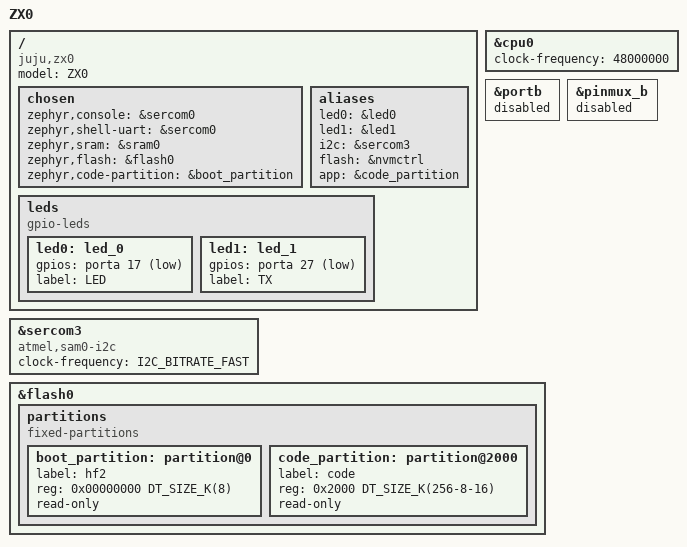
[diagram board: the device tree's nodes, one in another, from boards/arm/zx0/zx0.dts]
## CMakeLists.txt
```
# Copyright 2021 Google LLC
#
# Licensed under the Apache License, Version 2.0 (the "License");
# you may not use this file except in compliance with the License.
# You may obtain a copy of the License at
#
#      http://www.apache.org/licenses/LICENSE-2.0
#
# Unless required by applicable law or agreed to in writing, software
# distributed under the License is distributed on an "AS IS" BASIS,
# WITHOUT WARRANTIES OR CONDITIONS OF ANY KIND, either express or implied.
# See the License for the specific language governing permissions and
# limitations under the License.

cmake_minimum_required(VERSION 3.13.1)

list(APPEND BOARD_ROOT ${CMAKE_CURRENT_SOURCE_DIR})
set(BOARD zx0)

find_package(Zephyr REQUIRED HINTS $ENV{ZEPHYR_BASE})
project(zx0-bootloader)

target_sources(app PRIVATE src/main.cpp src/hf2.cpp src/i2c_sam0.cpp src/hal.cpp)
```

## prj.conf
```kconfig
#
# Copyright (c) 2021 Google LLC.
#
# SPDX-License-Identifier: Apache-2.0
#

# Disable everything to minimise the flash usage.
CONFIG_I2C=n
CONFIG_WATCHDOG=n
CONFIG_SPI=n
CONFIG_SERIAL=n
CONFIG_SAM0_EIC=n
CONFIG_MULTITHREADING=n
CONFIG_SYS_CLOCK_EXISTS=n
CONFIG_FAULT_DUMP=0
CONFIG_GEN_ISR_TABLES=n

CONFIG_BUILD_OUTPUT_HEX=y
CONFIG_SIZE_OPTIMIZATIONS=y
CONFIG_CPLUSPLUS=y
CONFIG_STD_CPP2A=y
CONFIG_IS_BOOTLOADER=y

CONFIG_FLASH=y
CONFIG_GPIO=y
CONFIG_PINMUX=y
CONFIG_SOC_FLASH_SAM0=y
```

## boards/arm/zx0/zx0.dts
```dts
/*
 * Copyright (c) 2021 Google LLC.
 *
 * SPDX-License-Identifier: Apache-2.0
 */

/dts-v1/;
#include <atmel/samd21.dtsi>

/ {
	model = "ZX0";
	compatible = "juju,zx0", "atmel,samd21e18a", "atmel,samd21";

	chosen {
		zephyr,console = &sercom0;
		zephyr,shell-uart = &sercom0;
		zephyr,sram = &sram0;
		zephyr,flash = &flash0;
		zephyr,code-partition = &boot_partition;
	};

	aliases {
		led0 = &led0;
		led1 = &led1;
		i2c = &sercom3;
		flash = &nvmctrl;
		app = &code_partition;
	};

	leds {
		compatible = "gpio-leds";
		led0: led_0 {
			gpios = <&porta 17 GPIO_ACTIVE_LOW>;
			label = "LED";
		};
		led1: led_1 {
			gpios = <&porta 27 GPIO_ACTIVE_LOW>;
			label = "TX";
		};
	};

};

&cpu0 {
	clock-frequency = <48000000>;
};

&portb {
	status = "disabled";
};

&pinmux_b {
	status = "disabled";
};

&sercom3 {
	status = "okay";
	compatible = "atmel,sam0-i2c";
	clock-frequency = <I2C_BITRATE_FAST>;
	#address-cells = <1>;
	#size-cells = <0>;
};

&flash0 {
	partitions {
		compatible = "fixed-partitions";
		#address-cells = <1>;
		#size-cells = <1>;

		boot_partition: partition@0 {
			label = "hf2";
			reg = <0x00000000 DT_SIZE_K(8)>;
			read-only;
		};

		code_partition: partition@2000 {
			label = "code";
			reg = <0x2000 DT_SIZE_K(256-8-16)>;
			read-only;
		};
	};
};
```

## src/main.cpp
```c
// Copyright 2021 Google LLC
//
// Licensed under the Apache License, Version 2.0 (the "License");
// you may not use this file except in compliance with the License.
// You may obtain a copy of the License at
//
//      http://www.apache.org/licenses/LICENSE-2.0
//
// Unless required by applicable law or agreed to in writing, software
// distributed under the License is distributed on an "AS IS" BASIS,
// WITHOUT WARRANTIES OR CONDITIONS OF ANY KIND, either express or implied.
// See the License for the specific language governing permissions and
// limitations under the License.

#include "hal.h"
#include "hf2.h"
#include "i2c_sam0.h"

static I2C i2c((SercomI2cs *)DT_REG_ADDR(DT_ALIAS(i2c)));
static HF2 hf2(HAL::flash);

void I2C::received(const uint8_t *in, uint8_t *out) { hf2.packet(in, out); }

void main(void) {
    HAL::enter_app();

    HAL::init();
    i2c.init();

    for (;;) {
        gpio_pin_toggle(HAL::led0.port, HAL::led0.pin);
        for (int spin = 0; spin < 200 * (HAL::kCyclesPerSec / 48000); spin++) {
            i2c.poll();
        }
    }
}
```

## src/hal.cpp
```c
// Copyright 2021 Google LLC
//
// Licensed under the Apache License, Version 2.0 (the "License");
// you may not use this file except in compliance with the License.
// You may obtain a copy of the License at
//
//      http://www.apache.org/licenses/LICENSE-2.0
//
// Unless required by applicable law or agreed to in writing, software
// distributed under the License is distributed on an "AS IS" BASIS,
// WITHOUT WARRANTIES OR CONDITIONS OF ANY KIND, either express or implied.
// See the License for the specific language governing permissions and
// limitations under the License.

#include "hal.h"

#include <drivers/gpio.h>

const struct gpio_dt_spec HAL::led0 = GPIO_DT_SPEC_GET_OR(DT_ALIAS(led0), gpios, {0});
const struct gpio_dt_spec HAL::led1 = GPIO_DT_SPEC_GET_OR(DT_ALIAS(led1), gpios, {0});
const device *HAL::flash = DEVICE_DT_GET(DT_ALIAS(flash));

enum class DoubleTap : uint32_t {
    None = 0,
    Magic = 0xf01669ef,
    QuickBoot = 0xf02669ef,
};

DoubleTap &double_tap = *(DoubleTap *)(HMCRAMC0_ADDR + HMCRAMC0_SIZE - 4);

void HAL::init() {
    gpio_pin_configure_dt(&led0, GPIO_OUTPUT_INACTIVE);
    gpio_pin_configure_dt(&led1, GPIO_OUTPUT_INACTIVE);
}

static void wait(uint32_t millis) {
    millis *= HAL::kCyclesPerSec / 10000;

    while (millis--) {
        asm("nop; nop; nop; nop; nop");
    }
}

int HAL::enter_app() {
    uint32_t start = *(uint32_t *)(kAppStart + 4);

    if (start <= kAppStart || start >= FLASH_SIZE) {
        /* Stay in bootloader */
        return -ENOENT;
    }

    auto state = double_tap;
    double_tap = DoubleTap::None;

    if (PM->RCAUSE.bit.POR) {
        // Just turned on, continue straight into the app.
    } else {
        switch (state) {
            case DoubleTap::Magic:
                return 0;
            case DoubleTap::QuickBoot:
                break;
            default:
                double_tap = DoubleTap::Magic;
                // Spin to give the user time to press reset again.
                wait(500);
                double_tap = DoubleTap::None;
                break;
        }
    }

    // Enter the app.
    __set_MSP(*(uint32_t *)kAppStart);
    SCB->VTOR = (kAppStart & SCB_VTOR_TBLOFF_Msk);
    asm("bx %0" ::"r"(start));

    return 0;
}
```

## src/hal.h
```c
// Copyright 2021 Google LLC
//
// Licensed under the Apache License, Version 2.0 (the "License");
// you may not use this file except in compliance with the License.
// You may obtain a copy of the License at
//
//      http://www.apache.org/licenses/LICENSE-2.0
//
// Unless required by applicable law or agreed to in writing, software
// distributed under the License is distributed on an "AS IS" BASIS,
// WITHOUT WARRANTIES OR CONDITIONS OF ANY KIND, either express or implied.
// See the License for the specific language governing permissions and
// limitations under the License.

#pragma once

#include <device.h>
#include <drivers/gpio.h>
#include <soc.h>

// Hardware abstraction. Contains the flash details, LEDs, and other devices.
class HAL {
   public:
    // Initialise the common devices.
    static void init();
    // Try to enter the application. Returns if the application is invalid.
    static int enter_app();

    static constexpr size_t kFlashSize = FLASH_SIZE;
    static constexpr size_t kPageSize = NVMCTRL_ROW_SIZE;
    static constexpr size_t kNumPages = kFlashSize / kPageSize;
    static constexpr uintptr_t kAppStart = DT_REG_ADDR(DT_ALIAS(app));
    static constexpr int kCyclesPerSec = CONFIG_SYS_CLOCK_HW_CYCLES_PER_SEC;

    static const struct gpio_dt_spec led0;
    static const struct gpio_dt_spec led1;
    static const device *flash;
};
```

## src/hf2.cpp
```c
// Copyright 2021 Google LLC
//
// Licensed under the Apache License, Version 2.0 (the "License");
// you may not use this file except in compliance with the License.
// You may obtain a copy of the License at
//
//      http://www.apache.org/licenses/LICENSE-2.0
//
// Unless required by applicable law or agreed to in writing, software
// distributed under the License is distributed on an "AS IS" BASIS,
// WITHOUT WARRANTIES OR CONDITIONS OF ANY KIND, either express or implied.
// See the License for the specific language governing permissions and
// limitations under the License.

#include "hf2.h"

#include <drivers/flash.h>
#include <drivers/gpio.h>
#include <string.h>
#include <sys/crc.h>

struct WriteFlashPage {
    uint32_t target_addr;
    uint8_t data[0];
};

struct ChksumPages {
    uint32_t target_addr;
    uint32_t num_pages;
};

struct ReadWords {
    uint32_t target_addr;
    uint32_t num_words;
};

struct Command {
    enum class ID : uint32_t {
        BININFO = 1,
        INFO = 2,
        RESET_INTO_APP = 3,
        RESET_INTO_BOOTLOADER = 4,
        START_FLASH = 5,
        WRITE_FLASH_PAGE = 6,
        CHKSUM_PAGES = 7,
        READ_WORDS = 8,
        WRITE_WORDS = 9,
    };

    ID command_id;
    uint16_t tag;
    uint8_t reserved0;
    uint8_t reserved1;

    union {
        WriteFlashPage write_flash_page;
        ChksumPages chksum_pages;
        ReadWords read_words;
    };
};

struct Header {
    enum class Status : uint8_t {
        OK,
        Invalid,
        Error,
    };

    uint16_t tag;
    Status status;
    uint8_t status_info;
};

struct BinInfo {
    enum class Mode : uint32_t {
        Bootloader = 1,
        UserSpace = 2,
    };

    Mode mode;
    uint32_t flash_page_size;
    uint32_t flash_num_pages;
    uint32_t max_message_size;
    uint32_t family_id;
};

struct Response {
    Header header;

    union {
        BinInfo bininfo;
        uint16_t chksums[8];
        uint32_t read_words[4];
    };
};

// Must fit within a 32 byte I2C response.
static_assert(sizeof(Command) <= 30);
static_assert(sizeof(Response) <= 30);

void HF2::packet(const uint8_t *in, uint8_t *out) {
    uint8_t header = in[0];
    if ((header & StdinStderr) != 0) {
        return;
    }

    auto size = header & SizeMask;
    size_t end = at_ + size;
    if (end >= sizeof(message_)) {
        return;
    }

    memcpy(message_ + at_, in + 1, size);
    at_ += size;

    if ((header & Final) == 0) {
        return;
    }

    at_ = 0;

    Response resp;
    auto wrote = message(*(Command *)message_, resp);
    memcpy(out + 2, &resp, wrote);
    out[0] = wrote + 1;
    out[1] = wrote | Final;
}

size_t HF2::bininfo(BinInfo &resp) {
    resp = {
        .mode = BinInfo::Mode::Bootloader,
        .flash_page_size = HAL::kPageSize,
        .flash_num_pages = HAL::kNumPages,
        .max_message_size = sizeof(message_),
        .family_id = 1234,
    };
    return sizeof(BinInfo);
}

size_t HF2::chksum_pages(uint32_t addr, uint32_t pages, uint16_t *chksums) {
    if (pages > ARRAY_SIZE(Response::chksums)) {
        return -ENOMEM;
    }
    for (uint32_t i = 0; i < pages; i++) {
        chksums[i] = crc16_itu_t(0, (uint8_t *)addr + i * HAL::kPageSize, HAL::kPageSize);
    }
    return pages * sizeof(*chksums);
}

size_t HF2::write_flash_page(uint32_t addr, const uint8_t *data) {
    int err = flash_erase(flash_, addr, HAL::kPageSize);
    if (err != 0) {
        return err;
    }
    return flash_write(flash_, addr, data, HAL::kPageSize);
}

size_t HF2::reset_into_app() { return HAL::enter_app(); }

size_t HF2::read_words(uint32_t addr, uint32_t count, uint32_t *words) {
    if (count > ARRAY_SIZE(Response::read_words)) {
        return -ENOMEM;
    }
    for (uint32_t i = 0; i < count; i++) {
        words[i] = ((uint32_t *)addr)[i];
    }
    return count * sizeof(*words);
}

size_t HF2::message(Command &command, Response &resp) {
    gpio_pin_toggle(HAL::led1.port, HAL::led1.pin);

    int err = -EINVAL;

    switch (command.command_id) {
        case Command::ID::BININFO:
            err = bininfo(resp.bininfo);
            break;
        case Command::ID::INFO:
        case Command::ID::WRITE_WORDS:
            err = -ENOENT;
            break;
        case Command::ID::RESET_INTO_APP:
            err = reset_into_app();
            break;
        case Command::ID::RESET_INTO_BOOTLOADER:
        case Command::ID::START_FLASH:
            err = 0;
            break;
        case Command::ID::WRITE_FLASH_PAGE:
            err = write_flash_page(command.write_flash_page.target_addr,
                                   command.write_flash_page.data);
            break;
        case Command::ID::CHKSUM_PAGES:
            err = chksum_pages(command.chksum_pages.target_addr, command.chksum_pages.num_pages,
                               resp.chksums);
            break;
        case Command::ID::READ_WORDS:
            err = read_words(command.read_words.target_addr, command.read_words.num_words,
                             resp.read_words);
            break;
        default:
            break;
    }

    if (err < 0) {
        resp.header = {
            .tag = command.tag,
            .status = Header::Status::Error,
            .status_info = static_cast<uint8_t>(-err),
        };
        return sizeof(Header);
    }

    resp.header = {
        .tag = command.tag,
        .status = Header::Status::OK,
        .status_info = 0,
    };
    return sizeof(Header) + err;
}
```

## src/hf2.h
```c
/*
 * Copyright 2021 Google LLC
 *
 * Licensed under the Apache License, Version 2.0 (the "License");
 * you may not use this file except in compliance with the License.
 * You may obtain a copy of the License at
 *
 *      http://www.apache.org/licenses/LICENSE-2.0
 *
 * Unless required by applicable law or agreed to in writing, software
 * distributed under the License is distributed on an "AS IS" BASIS,
 * WITHOUT WARRANTIES OR CONDITIONS OF ANY KIND, either express or implied.
 * See the License for the specific language governing permissions and
 * limitations under the License.
 */

#pragma once

#include <device.h>

#include "hal.h"

struct Command;
struct Response;
struct BinInfo;

// Implements the Microsoft HF2 flashing protocol. See
// https://github.com/microsoft/uf2/blob/master/hf2.md for more.
class HF2 {
   public:
    HF2(const device *flash) : flash_(flash) {}

    // Called when a packet has been received from the lower layer. Any response will be written to
    // `out`. `out` must be at least 32 bytes.
    void packet(const uint8_t *in, uint8_t *out);

   private:
    // Header flags.
    enum Flag {
        Inner = 0x00,
        Final = 0x40,
        StdinStderr = 0x80,
        TypeMask = 0xC0,
        SizeMask = 63,
    };

    // Called once the packets have been decoded into a message. Dispatches the command, fills in
    // the response, and returns the size of the response in bytes.
    size_t message(Command &command, Response &resp);

    size_t bininfo(BinInfo &resp);
    size_t chksum_pages(uint32_t addr, uint32_t pages, uint16_t *chksums);
    size_t write_flash_page(uint32_t addr, const uint8_t *data);
    size_t reset_into_app();
    size_t read_words(uint32_t addr, uint32_t count, uint32_t *words);

    uint8_t message_[HAL::kPageSize * 3 / 2];
    uint16_t at_ = 0;
    const device *flash_;
};
```

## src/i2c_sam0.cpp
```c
// Copyright 2021 Google LLC
//
// Licensed under the Apache License, Version 2.0 (the "License");
// you may not use this file except in compliance with the License.
// You may obtain a copy of the License at
//
//      http://www.apache.org/licenses/LICENSE-2.0
//
// Unless required by applicable law or agreed to in writing, software
// distributed under the License is distributed on an "AS IS" BASIS,
// WITHOUT WARRANTIES OR CONDITIONS OF ANY KIND, either express or implied.
// See the License for the specific language governing permissions and
// limitations under the License.

#include "i2c_sam0.h"

static constexpr uint8_t kCommand = 0xFE;

void I2C::init() {
    GCLK->CLKCTRL.reg = GCLK_CLKCTRL_ID_SERCOM3_CORE | GCLK_CLKCTRL_CLKEN | GCLK_CLKCTRL_GEN_GCLK0;
    PM->APBCMASK.bit.SERCOM3_ = 1;

    regs_->CTRLA.bit.SWRST = 1;
    while (regs_->SYNCBUSY.reg) {
    }

    regs_->CTRLA.reg = SERCOM_I2CS_CTRLA_MODE_I2C_SLAVE;
    regs_->CTRLB.reg = SERCOM_I2CS_CTRLB_SMEN;
    regs_->ADDR.reg = SERCOM_I2CS_ADDR_ADDR(0x22);

    while (regs_->SYNCBUSY.reg) {
    }
    regs_->CTRLA.bit.ENABLE = 1;
}

void I2C::poll() {
    uint32_t flags = regs_->INTFLAG.reg;

    if (flags & SERCOM_I2CS_INTFLAG_PREC) {
        regs_->INTFLAG.reg = SERCOM_I2CS_INTFLAG_PREC;
        // STOP received.
        if (!read_) {
            received(input_buf_, output_buf_);
        }
        have_command_ = false;
    }
    if (flags & SERCOM_I2CS_INTFLAG_AMATCH) {
        regs_->INTFLAG.reg = SERCOM_I2CS_INTFLAG_AMATCH;
        at_ = 0;
        read_ = regs_->STATUS.bit.DIR;
    }
    if (flags & SERCOM_I2CS_INTFLAG_DRDY) {
        // Flag is cleared by hardware when DATA is read or written.
        if (!read_) {
            uint8_t data = regs_->DATA.reg;
            if (!have_command_) {
                if (data == kCommand) {
                    have_command_ = true;
                    ok_ = true;
                }
            } else if (have_command_ && at_ < sizeof(input_buf_)) {
                input_buf_[at_++] = data;
            } else {
                // Overflow or bad command, discard.
            }
        } else {
            if (have_command_ && at_ < sizeof(output_buf_)) {
                regs_->DATA.reg = output_buf_[at_++];
            } else {
                regs_->DATA.reg = 0;
            }
        }
    }
}
```

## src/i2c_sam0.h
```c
// Copyright 2021 Google LLC
//
// Licensed under the Apache License, Version 2.0 (the "License");
// you may not use this file except in compliance with the License.
// You may obtain a copy of the License at
//
//      http://www.apache.org/licenses/LICENSE-2.0
//
// Unless required by applicable law or agreed to in writing, software
// distributed under the License is distributed on an "AS IS" BASIS,
// WITHOUT WARRANTIES OR CONDITIONS OF ANY KIND, either express or implied.
// See the License for the specific language governing permissions and
// limitations under the License.

#pragma once

#include <soc.h>

// I2C client implementation. Call poll() repeatably. Once a frame is received, received() will be
// called.
class I2C {
   public:
    I2C(SercomI2cs *regs) : regs_(regs) {}
    // Initialise the hardware.
    void init();

    // Poll for any incoming data.
    void poll();

    // Called once a packet has been received. The callee can write any response into `out`.
    void received(const uint8_t *in, uint8_t *out);

   private:
    SercomI2cs *regs_;

    uint8_t input_buf_[64];
    uint8_t output_buf_[64];

    bool have_command_ = false;
    bool read_;
    uint8_t at_;
    bool ok_;
};
```
